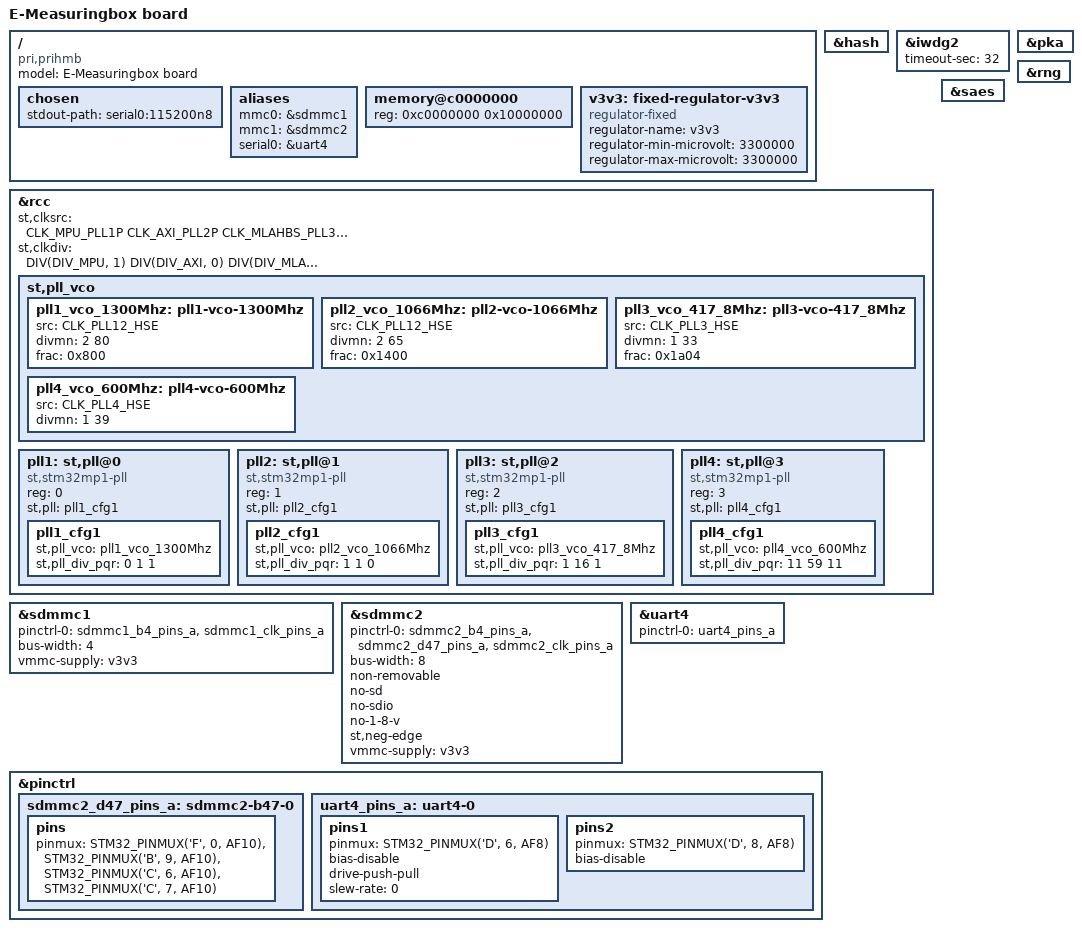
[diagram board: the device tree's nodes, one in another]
// SPDX-License-Identifier: (GPL-2.0+ OR BSD-3-Clause)
/*
 * Copyright (C) 2023, Protonic Holland - All Rights Reserved
 * Author: Roan van Dijk <roan@protonic.nl>
 */
/dts-v1/;

#include "stm32mp133.dtsi"
#include "stm32mp13-pinctrl.dtsi"
#include "stm32mp13xc.dtsi"
#include <dt-bindings/clock/stm32mp13-clksrc.h>
#include "stm32mp13-ddr3-1x2Gb-1066-binF.dtsi"

/ {
	model = "E-Measuringbox board";
	compatible = "pri,prihmb", "st,stm32mp133";

	chosen {
		stdout-path = "serial0:115200n8";
	};

	aliases {
		mmc0 = &sdmmc1;
		mmc1 = &sdmmc2;
		serial0 = &uart4;
	};

	memory@c0000000 {
		device_type = "memory";
		reg = <0xc0000000 0x10000000>;
	};

	v3v3: fixed-regulator-v3v3 {
		compatible = "regulator-fixed";
		regulator-name = "v3v3";
		regulator-min-microvolt = <3300000>;
		regulator-max-microvolt = <3300000>;
	};
};

&hash {
	status = "okay";
};

&iwdg2 {
	timeout-sec = <32>;
	status = "okay";
};

&pka {
	status = "okay";
};

&rcc {
	st,clksrc = <
		CLK_MPU_PLL1P
		CLK_AXI_PLL2P
		CLK_MLAHBS_PLL3
		CLK_CKPER_HSE
		CLK_RTC_LSE
		CLK_SDMMC1_PLL4P
		CLK_SDMMC2_PLL4P
		CLK_STGEN_HSE
		CLK_USBPHY_HSE
		CLK_USBO_USBPHY
		CLK_I2C12_HSI
		CLK_UART4_HSI
		CLK_UART6_HSI
		CLK_UART78_HSI
		CLK_SAES_AXI
	>;

	st,clkdiv = <
		DIV(DIV_MPU, 1)
		DIV(DIV_AXI, 0)
		DIV(DIV_MLAHB, 0)
		DIV(DIV_APB1, 1)
		DIV(DIV_APB2, 1)
		DIV(DIV_APB3, 1)
		DIV(DIV_APB4, 1)
		DIV(DIV_APB5, 2)
		DIV(DIV_APB6, 1)
		DIV(DIV_RTC, 0)
	>;

	st,pll_vco {
		pll1_vco_1300Mhz: pll1-vco-1300Mhz {
			src = < CLK_PLL12_HSE >;
			divmn = < 2 80 >;
			frac = < 0x800 >;
		};

		pll2_vco_1066Mhz: pll2-vco-1066Mhz {
			src = < CLK_PLL12_HSE >;
			divmn = < 2 65 >;
			frac = < 0x1400 >;
		};

		pll3_vco_417_8Mhz: pll3-vco-417_8Mhz {
			src = < CLK_PLL3_HSE >;
			divmn = < 1 33 >;
			frac = < 0x1a04 >;
		};

		pll4_vco_600Mhz: pll4-vco-600Mhz {
			src = < CLK_PLL4_HSE >;
			divmn = < 1 39 >;
		};
	};

	/* VCO = 1300.0 MHz => P = 650 (CPU) */
	pll1:st,pll@0 {
		compatible = "st,stm32mp1-pll";
		reg = <0>;

		st,pll = < &pll1_cfg1 >;

		pll1_cfg1: pll1_cfg1 {
			st,pll_vco = < &pll1_vco_1300Mhz >;
			st,pll_div_pqr = < 0 1 1 >;
		};
	};

	/* VCO = 1066.0 MHz => P = 266 (AXI), Q = 266, R = 533 (DDR) */
	pll2:st,pll@1 {
		compatible = "st,stm32mp1-pll";
		reg = <1>;

		st,pll = < &pll2_cfg1 >;

		pll2_cfg1: pll2_cfg1 {
			st,pll_vco = < &pll2_vco_1066Mhz >;
			st,pll_div_pqr = < 1 1 0 >;
		};
	};

	/* VCO = 417.8 MHz => P = 209, Q = 24, R = 209 */
	pll3:st,pll@2 {
		compatible = "st,stm32mp1-pll";
		reg = <2>;

		st,pll = < &pll3_cfg1 >;

		pll3_cfg1: pll3_cfg1 {
			st,pll_vco = < &pll3_vco_417_8Mhz >;
			st,pll_div_pqr = < 1 16 1 >;
		};
	};

	/* VCO = 600.0 MHz => P = 120, Q = 40, R = 96 */
	pll4:st,pll@3 {
		compatible = "st,stm32mp1-pll";
		reg = <3>;

		st,pll = < &pll4_cfg1 >;

		pll4_cfg1: pll4_cfg1 {
			st,pll_vco = < &pll4_vco_600Mhz >;
			st,pll_div_pqr = < 11 59 11 >;
		};
	};
};

&rng {
	status = "okay";
};

&saes {
	status = "okay";
};

&sdmmc1 {
	pinctrl-names = "default";
	pinctrl-0 = <&sdmmc1_b4_pins_a &sdmmc1_clk_pins_a>;
	bus-width = <4>;
	vmmc-supply = <&v3v3>;
	status = "okay";
};

&sdmmc2 {
	pinctrl-names = "default";
	pinctrl-0 = <&sdmmc2_b4_pins_a &sdmmc2_d47_pins_a &sdmmc2_clk_pins_a>;
	bus-width = <8>;
	non-removable;
	no-sd;
	no-sdio;
	no-1-8-v;
	st,neg-edge;
	vmmc-supply = <&v3v3>;
	status = "okay";
};

&uart4 {
	pinctrl-names = "default";
	pinctrl-0 = <&uart4_pins_a>;
	status = "okay";
};

&pinctrl {
	sdmmc2_d47_pins_a: sdmmc2-b47-0 {
		pins {
			pinmux = <STM32_PINMUX('F', 0, AF10)>, /* SDMMC2_D4 */
				 <STM32_PINMUX('B', 9, AF10)>, /* SDMMC2_D5 */
				 <STM32_PINMUX('C', 6, AF10)>, /* SDMMC2_D6 */
				 <STM32_PINMUX('C', 7, AF10)>; /* SDMMC2_D7 */
		};
	};

	uart4_pins_a: uart4-0 {
		pins1 {
			pinmux = <STM32_PINMUX('D', 6, AF8)>; /* UART4_TX */
			bias-disable;
			drive-push-pull;
			slew-rate = <0>;
		};
		pins2 {
			pinmux = <STM32_PINMUX('D', 8, AF8)>; /* UART4_RX */
			bias-disable;
		};
	};
};
